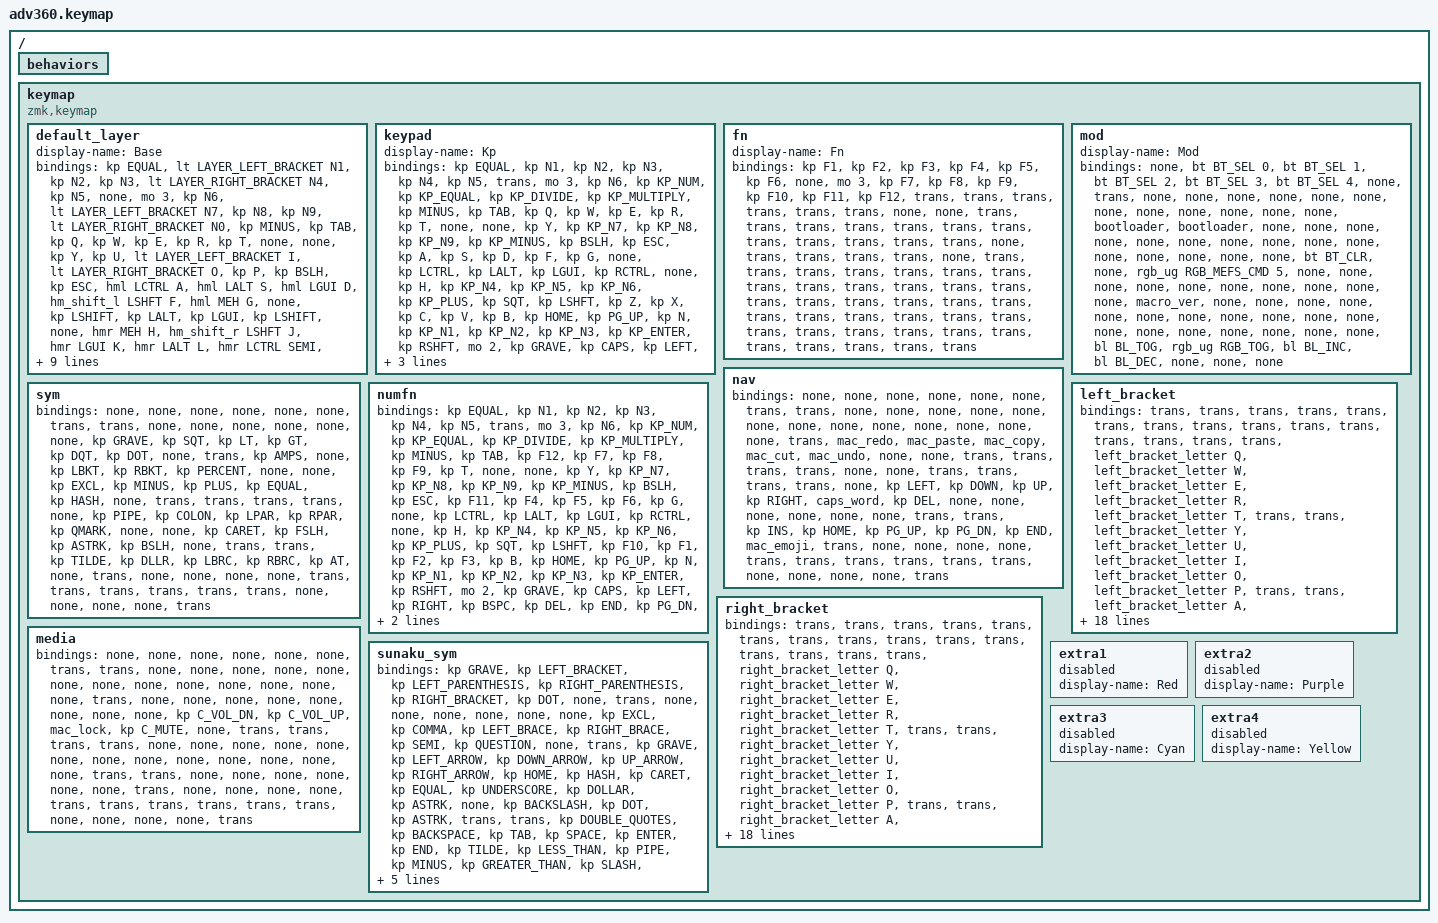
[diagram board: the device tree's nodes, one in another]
#include <behaviors.dtsi>
#include <dt-bindings/zmk/keys.h>
#include <dt-bindings/zmk/bt.h>
#include <dt-bindings/zmk/rgb.h>
#include <dt-bindings/zmk/stp.h>
#include <dt-bindings/zmk/backlight.h>
#include <dt-bindings/zmk/pointing.h>

// personal includes
#include "includes/settings.dtsi"

// layers
#define LAYER_BASE 0
#define LAYER_KEYPAD 1
#define LAYER_FN 2
#define LAYER_MOD 3
#define LAYER_NAV 4
#define LAYER_SYM 5
#define LAYER_NUMFN 6
#define LAYER_LEFT_BRACKET 7
#define LAYER_RIGHT_BRACKET 8
#define LAYER_MEDIA 9
#define LAYER_SUNAKU_SYM 10

#define MEH LC(LS(LALT))

// References for inspiration 
// Folke's config here https://github.com/folke/zmk-config/blob/41a45d999742f2e523b5e9bfb9791846d4d24bea/config/base.keymap#L20
// https://github.com/infused-kim/zmk-config/blob/chocofi/main/config/includes/behaviours_homerow_mods.dtsi

/ {
    behaviors {
      #include "macros.dtsi"
      #include "version.dtsi"
      #include "includes/mods.dtsi"
      #include "includes/macos_macros.dtsi"
      
      // This homerow mods definition came with the firmware update in Feb 2025. Keeping for reference for now
      //hm: homerow_mods {
          //compatible = "zmk,behavior-hold-tap";
          //label = "HOMEROW_MODS";
          //#binding-cells = <2>;
          //tapping-term-ms = <200>;
          //quick_tap_ms = <175>;
          //flavor = "tap-preferred";
          //bindings = <&kp>, <&kp>;
      //};
    };

  keymap {
    compatible = "zmk,keymap";

    default_layer {
      display-name = "Base";
      bindings = <
//    ┌──────────────┬────────────────┬─────────────┬─────────────┬────────────────────┬────────────┬─────┐                                                                                                                                                              ┌──────┬────────────┬────────────────────┬────────────────┬────────────────┬────────────────┬──────────────┐
//    │      =       │ lt laltYER_[ 1 │      2      │      3      │   lt laltYER_] 4   │     5      │     │                                                                                                                                                              │ mo 3 │     6      │   lt laltYER_[ 7   │       8        │       9        │ lt laltYER_] 0 │      -       │
//    ├──────────────┼────────────────┼─────────────┼─────────────┼────────────────────┼────────────┼─────┤                                                                                                                                                              ├──────┼────────────┼────────────────────┼────────────────┼────────────────┼────────────────┼──────────────┤
//    │     tab      │       Q        │      W      │      E      │         R          │     T      │     │                                                                                                                                                              │      │     Y      │         U          │ lt laltYER_[ I │ lt laltYER_] O │       P        │      \       │
//    ├──────────────┼────────────────┼─────────────┼─────────────┼────────────────────┼────────────┼─────┤                                 ┌──────┬──────────────────────┐       ┌───────────────────────┬──────────────────────┐                                       ├──────┼────────────┼────────────────────┼────────────────┼────────────────┼────────────────┼──────────────┤
//    │     esc      │  &hml lctl A   │ &hml lalt S │ &hml lgui D │ &hm_shift_l lsft F │ &hml MEH G │     │                                 │ lsft │         lalt         │       │         lgui          │         lsft         │                                       │      │ &hmr MEH H │ &hm_shift_r lsft J │  &hmr lgui K   │  &hmr lalt L   │  &hmr lctl ;   │      '       │
//    ├──────────────┼────────────────┼─────────────┼─────────────┼────────────────────┼────────────┼─────┘                                 └──────┼──────────────────────┤       ├───────────────────────┼──────────────────────┘                                       └──────┼────────────┼────────────────────┼────────────────┼────────────────┼────────────────┼──────────────┤
//    │ &smart_shift │       Z        │      X      │      C      │         V          │     B      │                                              │         home         │       │         pgup          │                                                                     │     N      │         M          │       ,        │       .        │       /        │ &smart_shift │
//    ├──────────────┼────────────────┼─────────────┼─────────────┼────────────────────┼────────────┘                 ┌─────────────────────┬──────┼──────────────────────┤       ├───────────────────────┼──────────────────────┬───────────────────────────┐                  └────────────┼────────────────────┼────────────────┼────────────────┼────────────────┼──────────────┤
//    │     mo 2     │                │             │             │                    │                              │ lt laltYER_NAV bspc │ del  │ lt laltYER_MEDIA end │       │ lt laltYER_MEDIA pgdn │ lt laltYER_NUMFN ent │ lt laltYER_SUNAKU_SYM spc │                               │                    │                │                │                │     mo 2     │
//    └──────────────┴────────────────┴─────────────┴─────────────┴────────────────────┘                              └─────────────────────┴──────┴──────────────────────┘       └───────────────────────┴──────────────────────┴───────────────────────────┘                               └────────────────────┴────────────────┴────────────────┴────────────────┴──────────────┘
  &kp EQUAL      &lt LAYER_LEFT_BRACKET N1   &kp N2        &kp N3        &lt LAYER_RIGHT_BRACKET N4   &kp N5       &none                                                                                                                                                                        &mo 3   &kp N6       &lt LAYER_LEFT_BRACKET N7   &kp N8                     &kp N9                      &lt LAYER_RIGHT_BRACKET N0   &kp MINUS
  &kp TAB        &kp Q                       &kp W         &kp E         &kp R                        &kp T        &none                                                                                                                                                                        &none   &kp Y        &kp U                       &lt LAYER_LEFT_BRACKET I   &lt LAYER_RIGHT_BRACKET O   &kp P                        &kp BSLH
  &kp ESC        &hml LCTRL A                &hml LALT S   &hml LGUI D   &hm_shift_l LSHFT F          &hml MEH G   &none                                    &kp LSHIFT   &kp LALT                      &kp LGUI                &kp LSHIFT                                                       &none   &hmr MEH H   &hm_shift_r LSHFT J         &hmr LGUI K                &hmr LALT L                 &hmr LCTRL SEMI              &kp SQT
  &smart_shift   &kp Z                       &kp X         &kp C         &kp V                        &kp B                                                              &kp HOME                      &kp PG_UP                                                                                        &kp N        &kp M                       &kp COMMA                  &kp DOT                     &kp FSLH                     &smart_shift
  &mo 2          &none                       &none         &none         &none                                                         &lt LAYER_NAV BSPC   &kp DEL      &lt LAYER_MEDIA END           &lt LAYER_MEDIA PG_DN   &lt LAYER_NUMFN ENTER   &lt LAYER_SUNAKU_SYM SPACE                                    &none                       &none                      &none                       &none                        &mo 2
      >;
    };
    keypad {
      display-name = "Kp";
      bindings = <
//    ┌──────┬───┬──────┬──────┬──────┬───┬─────┐                                                                      ┌──────┬───┬──────┬──────┬──────┬──────┬──────┐
//    │  =   │ 1 │  2   │  3   │  4   │ 5 │     │                                                                      │ mo 3 │ 6 │ nlck │ kp_= │ kp_/ │ kp_* │  -   │
//    ├──────┼───┼──────┼──────┼──────┼───┼─────┤                                                                      ├──────┼───┼──────┼──────┼──────┼──────┼──────┤
//    │ tab  │ Q │  W   │  E   │  R   │ T │     │                                                                      │      │ Y │  7   │  8   │  9   │ kp_- │  \   │
//    ├──────┼───┼──────┼──────┼──────┼───┼─────┤                  ┌──────┬──────┐       ┌──────┬──────┐               ├──────┼───┼──────┼──────┼──────┼──────┼──────┤
//    │ esc  │ A │  S   │  D   │  F   │ G │     │                  │ lctl │ lalt │       │ lgui │ rctl │               │      │ H │  4   │  5   │  6   │ kp_+ │  '   │
//    ├──────┼───┼──────┼──────┼──────┼───┼─────┘                  └──────┼──────┤       ├──────┼──────┘               └──────┼───┼──────┼──────┼──────┼──────┼──────┤
//    │ lsft │ Z │  X   │  C   │  V   │ B │                               │ home │       │ pgup │                             │ N │  1   │  2   │  3   │ ent  │ rsft │
//    ├──────┼───┼──────┼──────┼──────┼───┘                 ┌──────┬──────┼──────┤       ├──────┼──────┬───┐                  └───┼──────┼──────┼──────┼──────┼──────┤
//    │ mo 2 │ ` │ caps │ left │ rght │                     │ bspc │ del  │ end  │       │ pgdn │ ent  │ 0 │                      │  up  │ down │ kp_. │  ]   │ mo 2 │
//    └──────┴───┴──────┴──────┴──────┘                     └──────┴──────┴──────┘       └──────┴──────┴───┘                      └──────┴──────┴──────┴──────┴──────┘
  &kp EQUAL   &kp N1      &kp N2     &kp N3     &kp N4      &kp N5   &trans                                                                                                         &mo 3   &kp N6   &kp KP_NUM   &kp KP_EQUAL   &kp KP_DIVIDE   &kp KP_MULTIPLY   &kp MINUS
  &kp TAB     &kp Q       &kp W      &kp E      &kp R       &kp T    &none                                                                                                          &none   &kp Y    &kp KP_N7    &kp KP_N8      &kp KP_N9       &kp KP_MINUS      &kp BSLH
  &kp ESC     &kp A       &kp S      &kp D      &kp F       &kp G    &none                           &kp LCTRL   &kp LALT           &kp LGUI    &kp RCTRL                           &none   &kp H    &kp KP_N4    &kp KP_N5      &kp KP_N6       &kp KP_PLUS       &kp SQT
  &kp LSHFT   &kp Z       &kp X      &kp C      &kp V       &kp B                                                &kp HOME           &kp PG_UP                                               &kp N    &kp KP_N1    &kp KP_N2      &kp KP_N3       &kp KP_ENTER      &kp RSHFT
  &mo 2       &kp GRAVE   &kp CAPS   &kp LEFT   &kp RIGHT                                 &kp BSPC   &kp DEL     &kp END            &kp PG_DN   &kp ENTER   &kp KP_N0                                &kp UP       &kp DOWN       &kp KP_DOT      &kp RBKT          &mo 2
      >;
    };
    fn {
      display-name = "Fn";
      bindings = <
//    ┌─────┬─────┬─────┬─────┬─────┬─────┬─────┐                                                                   ┌──────┬─────┬─────┬─────┬─────┬─────┬─────┐
//    │ f1  │ f2  │ f3  │ f4  │ f5  │ f6  │     │                                                                   │ mo 3 │ f7  │ f8  │ f9  │ f10 │ f11 │ f12 │
//    ├─────┼─────┼─────┼─────┼─────┼─────┼─────┤                                                                   ├──────┼─────┼─────┼─────┼─────┼─────┼─────┤
//    │     │     │     │     │     │     │     │                                                                   │      │     │     │     │     │     │     │
//    ├─────┼─────┼─────┼─────┼─────┼─────┼─────┤                 ┌─────┬─────┐       ┌─────┬─────┐                 ├──────┼─────┼─────┼─────┼─────┼─────┼─────┤
//    │     │     │     │     │     │     │     │                 │     │     │       │     │     │                 │      │     │     │     │     │     │     │
//    ├─────┼─────┼─────┼─────┼─────┼─────┼─────┘                 └─────┼─────┤       ├─────┼─────┘                 └──────┼─────┼─────┼─────┼─────┼─────┼─────┤
//    │     │     │     │     │     │     │                             │     │       │     │                              │     │     │     │     │     │     │
//    ├─────┼─────┼─────┼─────┼─────┼─────┘                 ┌─────┬─────┼─────┤       ├─────┼─────┬─────┐                  └─────┼─────┼─────┼─────┼─────┼─────┤
//    │     │     │     │     │     │                       │     │     │     │       │     │     │     │                        │     │     │     │     │     │
//    └─────┴─────┴─────┴─────┴─────┘                       └─────┴─────┴─────┘       └─────┴─────┴─────┘                        └─────┴─────┴─────┴─────┴─────┘
  &kp F1   &kp F2   &kp F3   &kp F4   &kp F5   &kp F6   &none                                                                                         &mo 3   &kp F7   &kp F8   &kp F9   &kp F10   &kp F11   &kp F12
  &trans   &trans   &trans   &trans   &trans   &trans   &none                                                                                         &none   &trans   &trans   &trans   &trans    &trans    &trans
  &trans   &trans   &trans   &trans   &trans   &trans   &none                        &trans   &trans           &trans   &trans                        &none   &trans   &trans   &trans   &trans    &trans    &trans
  &trans   &trans   &trans   &trans   &trans   &trans                                         &trans           &trans                                         &trans   &trans   &trans   &trans    &trans    &trans
  &trans   &trans   &trans   &trans   &trans                                &trans   &trans   &trans           &trans   &trans   &trans                                &trans   &trans   &trans    &trans    &trans
      >;
    };
    mod {
      display-name = "Mod";
      bindings = <
//    ┌─────┬──────────┬──────────┬──────────┬────────────┬──────────┬──────┐                                                                              ┌──────────────────────┬─────┬─────────┬─────────┬─────┬─────┬─────┐
//    │     │ bt_sel 0 │ bt_sel 1 │ bt_sel 2 │  bt_sel 3  │ bt_sel 4 │      │                                                                              │                      │     │         │         │     │     │     │
//    ├─────┼──────────┼──────────┼──────────┼────────────┼──────────┼──────┤                                                                              ├──────────────────────┼─────┼─────────┼─────────┼─────┼─────┼─────┤
//    │     │          │          │          │            │          │ boot │                                                                              │         boot         │     │         │         │     │     │     │
//    ├─────┼──────────┼──────────┼──────────┼────────────┼──────────┼──────┤                 ┌─────┬─────┐       ┌────────┬─────────┐                     ├──────────────────────┼─────┼─────────┼─────────┼─────┼─────┼─────┤
//    │     │          │          │          │            │          │      │                 │     │     │       │ bt_clr │         │                     │ ug_ rguiB_MEFS_CMD 5 │     │         │         │     │     │     │
//    ├─────┼──────────┼──────────┼──────────┼────────────┼──────────┼──────┘                 └─────┼─────┤       ├────────┼─────────┘                     └──────────────────────┼─────┼─────────┼─────────┼─────┼─────┼─────┤
//    │     │          │          │          │ &macro_ver │          │                              │     │       │        │                                                      │     │         │         │     │     │     │
//    ├─────┼──────────┼──────────┼──────────┼────────────┼──────────┘                  ┌─────┬─────┼─────┤       ├────────┼─────────┬─────────┐                                  └─────┼─────────┼─────────┼─────┼─────┼─────┤
//    │     │          │          │          │            │                             │     │     │     │       │        │ bl_ tog │ ug_ tog │                                        │ bl_ br+ │ bl_ br- │     │     │     │
//    └─────┴──────────┴──────────┴──────────┴────────────┘                             └─────┴─────┴─────┘       └────────┴─────────┴─────────┘                                        └─────────┴─────────┴─────┴─────┴─────┘
  &none   &bt BT_SEL 0   &bt BT_SEL 1   &bt BT_SEL 2   &bt BT_SEL 3   &bt BT_SEL 4   &none                                                                                                             &trans                   &none   &none        &none        &none   &none   &none
  &none   &none          &none          &none          &none          &none          &bootloader                                                                                                       &bootloader              &none   &none        &none        &none   &none   &none
  &none   &none          &none          &none          &none          &none          &none                             &none   &none           &bt BT_CLR   &none                                      &rgb_ug RGB_MEFS_CMD 5   &none   &none        &none        &none   &none   &none
  &none   &none          &none          &none          &macro_ver     &none                                                    &none           &none                                                                            &none   &none        &none        &none   &none   &none
  &none   &none          &none          &none          &none                                                   &none   &none   &none           &none        &bl BL_TOG   &rgb_ug RGB_TOG                                                &bl BL_INC   &bl BL_DEC   &none   &none   &none
      >;
    };
    nav {
      bindings = <
//    ┌─────┬─────┬─────┬─────┬─────┬─────┬─────┐                                                                   ┌─────┬───────────┬────────────┬───────────┬──────────┬───────────┬────────────┐
//    │     │     │     │     │     │     │     │                                                                   │     │           │            │           │          │           │            │
//    ├─────┼─────┼─────┼─────┼─────┼─────┼─────┤                                                                   ├─────┼───────────┼────────────┼───────────┼──────────┼───────────┼────────────┤
//    │     │     │     │     │     │     │     │                                                                   │     │ &mac_redo │ &mac_paste │ &mac_copy │ &mac_cut │ &mac_undo │            │
//    ├─────┼─────┼─────┼─────┼─────┼─────┼─────┤                 ┌─────┬─────┐       ┌─────┬─────┐                 ├─────┼───────────┼────────────┼───────────┼──────────┼───────────┼────────────┤
//    │     │     │     │     │     │     │     │                 │     │     │       │     │     │                 │     │   left    │    down    │    up     │   rght   │   capsw   │    del     │
//    ├─────┼─────┼─────┼─────┼─────┼─────┼─────┘                 └─────┼─────┤       ├─────┼─────┘                 └─────┼───────────┼────────────┼───────────┼──────────┼───────────┼────────────┤
//    │     │     │     │     │     │     │                             │     │       │     │                             │    ins    │    home    │   pgup    │   pgdn   │    end    │ &mac_emoji │
//    ├─────┼─────┼─────┼─────┼─────┼─────┘                 ┌─────┬─────┼─────┤       ├─────┼─────┬─────┐                 └───────────┼────────────┼───────────┼──────────┼───────────┼────────────┤
//    │     │     │     │     │     │                       │     │     │     │       │     │     │     │                             │            │           │          │           │            │
//    └─────┴─────┴─────┴─────┴─────┘                       └─────┴─────┴─────┘       └─────┴─────┴─────┘                             └────────────┴───────────┴──────────┴───────────┴────────────┘
  &none    &none    &none    &none    &none    &none   &trans                                                                                         &trans   &none       &none        &none       &none       &none        &none
  &none    &none    &none    &none    &none    &none   &none                                                                                          &trans   &mac_redo   &mac_paste   &mac_copy   &mac_cut    &mac_undo    &none
  &none    &trans   &trans   &trans   &trans   &none   &none                         &trans   &trans           &trans   &trans                        &none    &kp LEFT    &kp DOWN     &kp UP      &kp RIGHT   &caps_word   &kp DEL
  &none    &none    &none    &none    &none    &none                                          &trans           &trans                                          &kp INS     &kp HOME     &kp PG_UP   &kp PG_DN   &kp END      &mac_emoji
  &trans   &none    &none    &none    &none                                 &trans   &trans   &trans           &trans   &trans   &trans                                    &none        &none       &none       &none        &trans
      >;
    };
    sym {
      bindings = <
//    ┌─────┬─────┬─────┬─────┬─────┬─────┬─────┐                                                                   ┌─────┬─────┬─────┬─────┬─────┬─────┬─────┐
//    │     │     │     │     │     │     │     │                                                                   │     │     │     │     │     │     │     │
//    ├─────┼─────┼─────┼─────┼─────┼─────┼─────┤                                                                   ├─────┼─────┼─────┼─────┼─────┼─────┼─────┤
//    │  `  │  '  │  <  │  >  │  "  │  .  │     │                                                                   │     │  &  │     │  [  │  ]  │  %  │     │
//    ├─────┼─────┼─────┼─────┼─────┼─────┼─────┤                 ┌─────┬─────┐       ┌─────┬─────┐                 ├─────┼─────┼─────┼─────┼─────┼─────┼─────┤
//    │     │  !  │  -  │  +  │  =  │  #  │     │                 │     │     │       │     │     │                 │     │  |  │  :  │  (  │  )  │  ?  │     │
//    ├─────┼─────┼─────┼─────┼─────┼─────┼─────┘                 └─────┼─────┤       ├─────┼─────┘                 └─────┼─────┼─────┼─────┼─────┼─────┼─────┤
//    │     │  ^  │  /  │  *  │  \  │     │                             │     │       │     │                             │  ~  │  $  │  {  │  }  │  @  │     │
//    ├─────┼─────┼─────┼─────┼─────┼─────┘                 ┌─────┬─────┼─────┤       ├─────┼─────┬─────┐                 └─────┼─────┼─────┼─────┼─────┼─────┤
//    │     │     │     │     │     │                       │     │     │     │       │     │     │     │                       │     │     │     │     │     │
//    └─────┴─────┴─────┴─────┴─────┘                       └─────┴─────┴─────┘       └─────┴─────┴─────┘                       └─────┴─────┴─────┴─────┴─────┘
  &none       &none       &none       &none       &none       &none      &trans                                                                                         &trans   &none       &none       &none      &none      &none         &none
  &kp GRAVE   &kp SQT     &kp LT      &kp GT      &kp DQT     &kp DOT    &none                                                                                          &trans   &kp AMPS    &none       &kp LBKT   &kp RBKT   &kp PERCENT   &none
  &none       &kp EXCL    &kp MINUS   &kp PLUS    &kp EQUAL   &kp HASH   &none                         &trans   &trans           &trans   &trans                        &none    &kp PIPE    &kp COLON   &kp LPAR   &kp RPAR   &kp QMARK     &none
  &none       &kp CARET   &kp FSLH    &kp ASTRK   &kp BSLH    &none                                             &trans           &trans                                          &kp TILDE   &kp DLLR    &kp LBRC   &kp RBRC   &kp AT        &none
  &trans      &none       &none       &none       &none                                       &trans   &trans   &trans           &trans   &trans   &trans                                    &none       &none      &none      &none         &trans
      >;
    };
    numfn {
      bindings = <
//    ┌──────┬─────┬──────┬──────┬──────┬───┬─────┐                                                                      ┌──────┬───┬──────┬──────┬──────┬──────┬──────┐
//    │  =   │  1  │  2   │  3   │  4   │ 5 │     │                                                                      │ mo 3 │ 6 │ nlck │ kp_= │ kp_/ │ kp_* │  -   │
//    ├──────┼─────┼──────┼──────┼──────┼───┼─────┤                                                                      ├──────┼───┼──────┼──────┼──────┼──────┼──────┤
//    │ tab  │ f12 │  f7  │  f8  │  f9  │ T │     │                                                                      │      │ Y │  7   │  8   │  9   │ kp_- │  \   │
//    ├──────┼─────┼──────┼──────┼──────┼───┼─────┤                  ┌──────┬──────┐       ┌──────┬──────┐               ├──────┼───┼──────┼──────┼──────┼──────┼──────┤
//    │ esc  │ f11 │  f4  │  f5  │  f6  │ G │     │                  │ lctl │ lalt │       │ lgui │ rctl │               │      │ H │  4   │  5   │  6   │ kp_+ │  '   │
//    ├──────┼─────┼──────┼──────┼──────┼───┼─────┘                  └──────┼──────┤       ├──────┼──────┘               └──────┼───┼──────┼──────┼──────┼──────┼──────┤
//    │ lsft │ f10 │  f1  │  f2  │  f3  │ B │                               │ home │       │ pgup │                             │ N │  1   │  2   │  3   │ ent  │ rsft │
//    ├──────┼─────┼──────┼──────┼──────┼───┘                 ┌──────┬──────┼──────┤       ├──────┼──────┬───┐                  └───┼──────┼──────┼──────┼──────┼──────┤
//    │ mo 2 │  `  │ caps │ left │ rght │                     │ bspc │ del  │ end  │       │ pgdn │ ent  │ 0 │                      │  up  │ down │ kp_. │  ]   │ mo 2 │
//    └──────┴─────┴──────┴──────┴──────┘                     └──────┴──────┴──────┘       └──────┴──────┴───┘                      └──────┴──────┴──────┴──────┴──────┘
  &kp EQUAL   &kp N1      &kp N2     &kp N3     &kp N4      &kp N5   &trans                                                                                                         &mo 3   &kp N6   &kp KP_NUM   &kp KP_EQUAL   &kp KP_DIVIDE   &kp KP_MULTIPLY   &kp MINUS
  &kp TAB     &kp F12     &kp F7     &kp F8     &kp F9      &kp T    &none                                                                                                          &none   &kp Y    &kp KP_N7    &kp KP_N8      &kp KP_N9       &kp KP_MINUS      &kp BSLH
  &kp ESC     &kp F11     &kp F4     &kp F5     &kp F6      &kp G    &none                           &kp LCTRL   &kp LALT           &kp LGUI    &kp RCTRL                           &none   &kp H    &kp KP_N4    &kp KP_N5      &kp KP_N6       &kp KP_PLUS       &kp SQT
  &kp LSHFT   &kp F10     &kp F1     &kp F2     &kp F3      &kp B                                                &kp HOME           &kp PG_UP                                               &kp N    &kp KP_N1    &kp KP_N2      &kp KP_N3       &kp KP_ENTER      &kp RSHFT
  &mo 2       &kp GRAVE   &kp CAPS   &kp LEFT   &kp RIGHT                                 &kp BSPC   &kp DEL     &kp END            &kp PG_DN   &kp ENTER   &kp KP_N0                                &kp UP       &kp DOWN       &kp KP_DOT      &kp RBKT          &mo 2
      >;
    };
    left_bracket {
      bindings = <
//    ┌─────┬────────────────────────┬────────────────────────┬────────────────────────┬────────────────────────┬────────────────────────┬─────┐                                                                   ┌─────┬────────────────────────┬────────────────────────┬────────────────────────┬────────────────────────┬────────────────────────┬─────┐
//    │     │                        │                        │                        │                        │                        │     │                                                                   │     │                        │                        │                        │                        │                        │     │
//    ├─────┼────────────────────────┼────────────────────────┼────────────────────────┼────────────────────────┼────────────────────────┼─────┤                                                                   ├─────┼────────────────────────┼────────────────────────┼────────────────────────┼────────────────────────┼────────────────────────┼─────┤
//    │     │ &left_bracket_letter Q │ &left_bracket_letter W │ &left_bracket_letter E │ &left_bracket_letter R │ &left_bracket_letter T │     │                                                                   │     │ &left_bracket_letter Y │ &left_bracket_letter U │ &left_bracket_letter I │ &left_bracket_letter O │ &left_bracket_letter P │     │
//    ├─────┼────────────────────────┼────────────────────────┼────────────────────────┼────────────────────────┼────────────────────────┼─────┤                 ┌─────┬─────┐       ┌─────┬─────┐                 ├─────┼────────────────────────┼────────────────────────┼────────────────────────┼────────────────────────┼────────────────────────┼─────┤
//    │     │ &left_bracket_letter A │ &left_bracket_letter S │ &left_bracket_letter D │ &left_bracket_letter F │ &left_bracket_letter G │     │                 │     │     │       │     │     │                 │     │ &left_bracket_letter H │ &left_bracket_letter J │ &left_bracket_letter K │ &left_bracket_letter L │                        │     │
//    ├─────┼────────────────────────┼────────────────────────┼────────────────────────┼────────────────────────┼────────────────────────┼─────┘                 └─────┼─────┤       ├─────┼─────┘                 └─────┼────────────────────────┼────────────────────────┼────────────────────────┼────────────────────────┼────────────────────────┼─────┤
//    │     │ &left_bracket_letter Z │ &left_bracket_letter X │ &left_bracket_letter C │ &left_bracket_letter V │ &left_bracket_letter B │                             │     │       │     │                             │ &left_bracket_letter N │ &left_bracket_letter M │                        │                        │                        │     │
//    ├─────┼────────────────────────┼────────────────────────┼────────────────────────┼────────────────────────┼────────────────────────┘                 ┌─────┬─────┼─────┤       ├─────┼─────┬─────┐                 └────────────────────────┼────────────────────────┼────────────────────────┼────────────────────────┼────────────────────────┼─────┤
//    │     │                        │                        │                        │                        │                                          │     │     │     │       │     │     │     │                                          │                        │                        │                        │                        │     │
//    └─────┴────────────────────────┴────────────────────────┴────────────────────────┴────────────────────────┘                                          └─────┴─────┴─────┘       └─────┴─────┴─────┘                                          └────────────────────────┴────────────────────────┴────────────────────────┴────────────────────────┴─────┘
  &trans   &trans                   &trans                   &trans                   &trans                   &trans                   &trans                                                                                         &trans   &trans                   &trans                   &trans                   &trans                   &trans                   &trans
  &trans   &left_bracket_letter Q   &left_bracket_letter W   &left_bracket_letter E   &left_bracket_letter R   &left_bracket_letter T   &trans                                                                                         &trans   &left_bracket_letter Y   &left_bracket_letter U   &left_bracket_letter I   &left_bracket_letter O   &left_bracket_letter P   &trans
  &trans   &left_bracket_letter A   &left_bracket_letter S   &left_bracket_letter D   &left_bracket_letter F   &left_bracket_letter G   &trans                        &trans   &trans           &trans   &trans                        &trans   &left_bracket_letter H   &left_bracket_letter J   &left_bracket_letter K   &left_bracket_letter L   &trans                   &trans
  &trans   &left_bracket_letter Z   &left_bracket_letter X   &left_bracket_letter C   &left_bracket_letter V   &left_bracket_letter B                                          &trans           &trans                                          &left_bracket_letter N   &left_bracket_letter M   &trans                   &trans                   &trans                   &trans
  &trans   &trans                   &trans                   &trans                   &trans                                                                 &trans   &trans   &trans           &trans   &trans   &trans                                                 &trans                   &trans                   &trans                   &trans                   &trans
      >;
    };
    right_bracket {
      bindings = <
//    ┌─────┬─────────────────────────┬─────────────────────────┬─────────────────────────┬─────────────────────────┬─────────────────────────┬─────┐                                                                   ┌─────┬─────────────────────────┬─────────────────────────┬─────────────────────────┬─────────────────────────┬─────────────────────────┬─────┐
//    │     │                         │                         │                         │                         │                         │     │                                                                   │     │                         │                         │                         │                         │                         │     │
//    ├─────┼─────────────────────────┼─────────────────────────┼─────────────────────────┼─────────────────────────┼─────────────────────────┼─────┤                                                                   ├─────┼─────────────────────────┼─────────────────────────┼─────────────────────────┼─────────────────────────┼─────────────────────────┼─────┤
//    │     │ &right_bracket_letter Q │ &right_bracket_letter W │ &right_bracket_letter E │ &right_bracket_letter R │ &right_bracket_letter T │     │                                                                   │     │ &right_bracket_letter Y │ &right_bracket_letter U │ &right_bracket_letter I │ &right_bracket_letter O │ &right_bracket_letter P │     │
//    ├─────┼─────────────────────────┼─────────────────────────┼─────────────────────────┼─────────────────────────┼─────────────────────────┼─────┤                 ┌─────┬─────┐       ┌─────┬─────┐                 ├─────┼─────────────────────────┼─────────────────────────┼─────────────────────────┼─────────────────────────┼─────────────────────────┼─────┤
//    │     │ &right_bracket_letter A │ &right_bracket_letter S │ &right_bracket_letter D │ &right_bracket_letter F │ &right_bracket_letter G │     │                 │     │     │       │     │     │                 │     │ &right_bracket_letter H │ &right_bracket_letter J │ &right_bracket_letter K │ &right_bracket_letter L │                         │     │
//    ├─────┼─────────────────────────┼─────────────────────────┼─────────────────────────┼─────────────────────────┼─────────────────────────┼─────┘                 └─────┼─────┤       ├─────┼─────┘                 └─────┼─────────────────────────┼─────────────────────────┼─────────────────────────┼─────────────────────────┼─────────────────────────┼─────┤
//    │     │ &right_bracket_letter Z │ &right_bracket_letter X │ &right_bracket_letter C │ &right_bracket_letter V │ &right_bracket_letter B │                             │     │       │     │                             │ &right_bracket_letter N │ &right_bracket_letter M │                         │                         │                         │     │
//    ├─────┼─────────────────────────┼─────────────────────────┼─────────────────────────┼─────────────────────────┼─────────────────────────┘                 ┌─────┬─────┼─────┤       ├─────┼─────┬─────┐                 └─────────────────────────┼─────────────────────────┼─────────────────────────┼─────────────────────────┼─────────────────────────┼─────┤
//    │     │                         │                         │                         │                         │                                           │     │     │     │       │     │     │     │                                           │                         │                         │                         │                         │     │
//    └─────┴─────────────────────────┴─────────────────────────┴─────────────────────────┴─────────────────────────┘                                           └─────┴─────┴─────┘       └─────┴─────┴─────┘                                           └─────────────────────────┴─────────────────────────┴─────────────────────────┴─────────────────────────┴─────┘
  &trans   &trans                    &trans                    &trans                    &trans                    &trans                    &trans                                                                                         &trans   &trans                    &trans                    &trans                    &trans                    &trans                    &trans
  &trans   &right_bracket_letter Q   &right_bracket_letter W   &right_bracket_letter E   &right_bracket_letter R   &right_bracket_letter T   &trans                                                                                         &trans   &right_bracket_letter Y   &right_bracket_letter U   &right_bracket_letter I   &right_bracket_letter O   &right_bracket_letter P   &trans
  &trans   &right_bracket_letter A   &right_bracket_letter S   &right_bracket_letter D   &right_bracket_letter F   &right_bracket_letter G   &trans                        &trans   &trans           &trans   &trans                        &trans   &right_bracket_letter H   &right_bracket_letter J   &right_bracket_letter K   &right_bracket_letter L   &trans                    &trans
  &trans   &right_bracket_letter Z   &right_bracket_letter X   &right_bracket_letter C   &right_bracket_letter V   &right_bracket_letter B                                          &trans           &trans                                          &right_bracket_letter N   &right_bracket_letter M   &trans                    &trans                    &trans                    &trans
  &trans   &trans                    &trans                    &trans                    &trans                                                                   &trans   &trans   &trans           &trans   &trans   &trans                                                  &trans                    &trans                    &trans                    &trans                    &trans
      >;
    };
    media {
      bindings = <
//    ┌─────┬─────┬──────┬──────┬───────────┬──────┬─────┐                                                                   ┌─────┬─────┬─────┬─────┬─────┬─────┬─────┐
//    │     │     │      │      │           │      │     │                                                                   │     │     │     │     │     │     │     │
//    ├─────┼─────┼──────┼──────┼───────────┼──────┼─────┤                                                                   ├─────┼─────┼─────┼─────┼─────┼─────┼─────┤
//    │     │     │      │      │           │      │     │                                                                   │     │     │     │     │     │     │     │
//    ├─────┼─────┼──────┼──────┼───────────┼──────┼─────┤                 ┌─────┬─────┐       ┌─────┬─────┐                 ├─────┼─────┼─────┼─────┼─────┼─────┼─────┤
//    │     │     │ vold │ volu │ &mac_lock │ mute │     │                 │     │     │       │     │     │                 │     │     │     │     │     │     │     │
//    ├─────┼─────┼──────┼──────┼───────────┼──────┼─────┘                 └─────┼─────┤       ├─────┼─────┘                 └─────┼─────┼─────┼─────┼─────┼─────┼─────┤
//    │     │     │      │      │           │      │                             │     │       │     │                             │     │     │     │     │     │     │
//    ├─────┼─────┼──────┼──────┼───────────┼──────┘                 ┌─────┬─────┼─────┤       ├─────┼─────┬─────┐                 └─────┼─────┼─────┼─────┼─────┼─────┤
//    │     │     │      │      │           │                        │     │     │     │       │     │     │     │                       │     │     │     │     │     │
//    └─────┴─────┴──────┴──────┴───────────┘                        └─────┴─────┴─────┘       └─────┴─────┴─────┘                       └─────┴─────┴─────┴─────┴─────┘
  &none    &none   &none          &none          &none       &none        &trans                                                                                         &trans   &none   &none   &none   &none   &none   &none
  &none    &none   &none          &none          &none       &none        &none                                                                                          &trans   &none   &none   &none   &none   &none   &none
  &none    &none   &kp C_VOL_DN   &kp C_VOL_UP   &mac_lock   &kp C_MUTE   &none                         &trans   &trans           &trans   &trans                        &none    &none   &none   &none   &none   &none   &none
  &none    &none   &none          &none          &none       &none                                               &trans           &trans                                          &none   &none   &none   &none   &none   &none
  &trans   &none   &none          &none          &none                                         &trans   &trans   &trans           &trans   &trans   &trans                                &none   &none   &none   &none   &trans
      >;
    };
    sunaku_sym {
      bindings = <
//    ┌─────┬───┬───┬───┬───┬───┬─────┐                                                             ┌─────┬─────┬──────┬──────┬─────┬──────┬──────┐
//    │  `  │ [ │ ( │ ) │ ] │ . │     │                                                             │     │     │      │      │     │      │      │
//    ├─────┼───┼───┼───┼───┼───┼─────┤                                                             ├─────┼─────┼──────┼──────┼─────┼──────┼──────┤
//    │  !  │ , │ { │ } │ ; │ ? │     │                                                             │     │  `  │ left │ down │ up  │ rght │ home │
//    ├─────┼───┼───┼───┼───┼───┼─────┤               ┌───┬───┐       ┌─────┬─────┐                 ├─────┼─────┼──────┼──────┼─────┼──────┼──────┤
//    │  #  │ ^ │ = │ _ │ $ │ * │     │               │ \ │ . │       │  *  │     │                 │     │  "  │ bspc │ tab  │ spc │ ent  │ end  │
//    ├─────┼───┼───┼───┼───┼───┼─────┘               └───┼───┤       ├─────┼─────┘                 └─────┼─────┼──────┼──────┼─────┼──────┼──────┤
//    │  ~  │ < │ | │ - │ > │ / │                         │ * │       │     │                             │  '  │ del  │      │     │      │      │
//    ├─────┼───┼───┼───┼───┼───┘                 ┌───┬───┼───┤       ├─────┼─────┬─────┐                 └─────┼──────┼──────┼─────┼──────┼──────┤
//    │     │ & │ ' │ " │ + │                     │ % │ : │ @ │       │     │     │     │                       │      │      │     │      │      │
//    └─────┴───┴───┴───┴───┘                     └───┴───┴───┘       └─────┴─────┴─────┘                       └──────┴──────┴─────┴──────┴──────┘
  &kp GRAVE   &kp LEFT_BRACKET   &kp LEFT_PARENTHESIS   &kp RIGHT_PARENTHESIS   &kp RIGHT_BRACKET   &kp DOT        &none                                                                                                             &trans   &none               &none            &none            &none          &none             &none
  &kp EXCL    &kp COMMA          &kp LEFT_BRACE         &kp RIGHT_BRACE         &kp SEMI            &kp QUESTION   &none                                                                                                             &trans   &kp GRAVE           &kp LEFT_ARROW   &kp DOWN_ARROW   &kp UP_ARROW   &kp RIGHT_ARROW   &kp HOME
  &kp HASH    &kp CARET          &kp EQUAL              &kp UNDERSCORE          &kp DOLLAR          &kp ASTRK      &none                             &kp BACKSLASH   &kp DOT               &kp ASTRK   &trans                        &trans   &kp DOUBLE_QUOTES   &kp BACKSPACE    &kp TAB          &kp SPACE      &kp ENTER         &kp END
  &kp TILDE   &kp LESS_THAN      &kp PIPE               &kp MINUS               &kp GREATER_THAN    &kp SLASH                                                        &kp ASTRK             &trans                                             &kp SINGLE_QUOTE    &kp DEL          &none            &none          &none             &none
  &trans      &kp AMPS           &kp SINGLE_QUOTE       &kp DOUBLE_QUOTES       &kp PLUS                                               &kp PERCENT   &kp COLON       &kp AT_SIGN           &trans      &trans   &trans                                            &none            &none            &none          &none             &trans
      >;
    };
    extra1 { 
      display-name = "Red";    
      status = "reserved";
    };

    extra2 { 
      display-name = "Purple";    
      status = "reserved";
    };

    extra3 { 
      display-name = "Cyan";    
      status = "reserved";
    };

    extra4 { 
      display-name = "Yellow";    
      status = "reserved";
    };
  };
};
